# PIC16LF1567 register map
Vendor: Microchip
Architecture 16Exxx. Special function registers and configuration words.
Registers are 8-bit, read-write, no defined reset value unless marked. A register's access mark holds for its fields unless they carry their own. Addresses are absolute, and some are shared; only a register's first bit layout is shown; lines under a group give offsets from that group; [hi:lo] are bit positions; {n}, {i} and the like mark numbered series; 'fields as' and 'values as' point back to an identical list; <NAME> marks a mode.

## Further device data
pins=1: RE3/ICDMCLR/MCLR/VPP; 2: RA0/ADTX20/PWM10/SS1/AN20; 3: RA1/ADTX10/PWM11/SS2/AN10; 4: RA2/ADTX0/PWM12/AN0/VREFMINUS; 5: RA3/ADTX1/PWM13/AN1/VREFPLUS; 6: RA4/ADTX2/T0CKI/AN2; 7: RA5/ADTX21/SS1/AN21; 8: RE0/ADTX30/AN30; 9: RE1/ADTX41/AN41; 10: RE2/ADTX31/AN31; 11: VDD; 12: VSS/AVSS; 13: RA7/ADTX11/AN11/CLKIN; 14: RA6/ADTX22/AN22/CLKOUT; 15: RC0/ADTX12/SDO2/T1CKI/AN12; 16: RC1/ADTX23/PWM2/SCK2/SCL2/AN23; 17: RC2/ADTX13/PWM1/SDI2/SDA2/AN13; 18: RC3/ADTX24/SCK1/SCL1/AN24; 19: RD0/ADTX42/AN42; 20: RD1/ADTX32/AN32; 21: RD2/ADTX43/AN43; 22: RD3/ADTX33/AN33; 23: RC4/ADTX14/SDI1/SDA1/AN14; 24: RC5/ADTX25/SDO1/AN25; 25: RC6/ADTX15/TX/CK/AN15; 26: RC7/ADTX26/RX/DT/AN26; 27: RD4/ADTX34/AN34; 28: RD5/ADTX44/AN44; 29: RD6/ADTX35/AN35; 30: RD7/ADTX45/AN45; 31: VSS; 32: VDD/AVDD; 33: RB0/IOCB0/INT/ADTX16/PWM20/AN16; 34: RB1/IOCB1/ADTX27/PWM21/AN27; 35: RB2/IOCB2/ADTX17/PWM22/AN17; 36: RB3/IOCB3/ADTX28/PWM23/AN28; 37: RB4/IOCB4/ADTX18/AD2GRDA/AD1GRDA/AN18; 38: RB5/IOCB5/ADTX29/T1G/AD2GRDA/AD1GRDA/AN29; 39: RB6/IOCB6/ADTX19/AD2GRDB/AD1GRDB/AN19/ICDCLK/ICSPCLK; 40: RB7/IOCB7/ADTX40/AD2GRDB/AD1GRDB/AN40/ICDDAT/ICSPDAT

## mssp
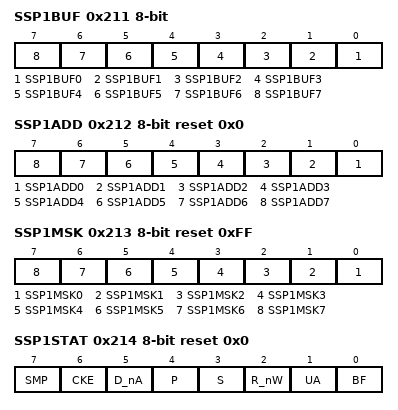
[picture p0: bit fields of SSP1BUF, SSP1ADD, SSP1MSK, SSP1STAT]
0x211 SSP1BUF — (power-on value xxxxxxxx)
  [n] SSP1BUF{n} (n=0..7)
0x212 SSP1ADD reset 0x0
  [n] SSP1ADD{n} (n=0..7)
0x213 SSP1MSK reset 0xFF
  [n] SSP1MSK{n} (n=0..7)
0x214 SSP1STAT reset 0x0
  [7] SMP, [6] CKE, [5] D_nA ro, [4] P ro, [3] S ro, [2] R_nW ro, [1] UA ro, [0] BF ro
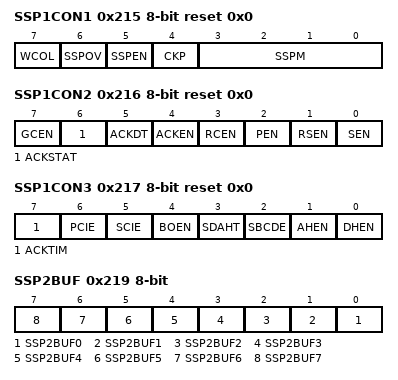
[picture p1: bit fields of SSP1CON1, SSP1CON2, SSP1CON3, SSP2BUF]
0x215 SSP1CON1 reset 0x0
  [7] WCOL, [6] SSPOV, [5] SSPEN, [4] CKP, [3:0] SSPM
0x216 SSP1CON2 reset 0x0
  [7] GCEN, [6] ACKSTAT ro, [5] ACKDT, [4] ACKEN, [3] RCEN, [2] PEN, [1] RSEN, [0] SEN
0x217 SSP1CON3 reset 0x0
  [7] ACKTIM ro, [6] PCIE, [5] SCIE, [4] BOEN, [3] SDAHT, [2] SBCDE, [1] AHEN, [0] DHEN
0x219 SSP2BUF — (power-on value xxxxxxxx)
  [n] SSP2BUF{n} (n=0..7)
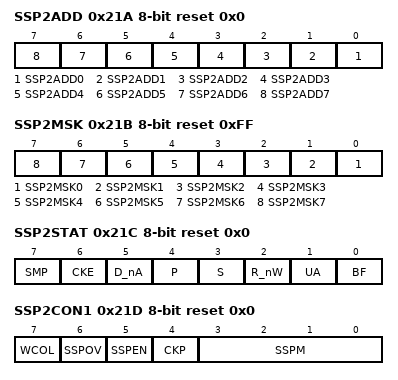
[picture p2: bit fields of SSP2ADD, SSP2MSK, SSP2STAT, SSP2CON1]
0x21A SSP2ADD reset 0x0
  [n] SSP2ADD{n} (n=0..7)
0x21B SSP2MSK reset 0xFF
  [n] SSP2MSK{n} (n=0..7)
0x21C SSP2STAT reset 0x0
  fields as SSP1STAT
0x21D SSP2CON1 reset 0x0
  [7] WCOL, [6] SSPOV, [5] SSPEN, [4] CKP, [3:0] SSPM
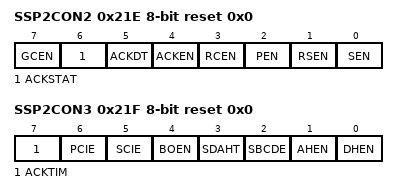
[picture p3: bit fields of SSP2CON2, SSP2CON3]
0x21E SSP2CON2 reset 0x0
  fields as SSP1CON2
0x21F SSP2CON3 reset 0x0
  fields as SSP1CON3

## CONFIG — Configuration words, addresses in ProgramSpace
0x8007 CONFIG1 14-bit reset 0x3FFF
  [11] CLKOUTEN — Clock Out Enable
    1=OFF (CLKOUT function is disabled. I/O or oscillator function on the CLKOUT pin); 0=ON (CLKOUT function is enabled on the CLKOUT pin)
  [10:9] BOREN — Brown-out Reset Enable
    3=ON (Brown-out Reset enabled); 2=NSLEEP (Brown-out Reset enabled while running and disabled in Sleep. SBOREN bit is ignored.); 1=SBODEN (Brown-out Reset controlled by the SBOREN bit in the BORCON register); 0=OFF (Brown-out Reset disabled. SBOREN bit is ignored.)
  [7] CP — Flash Program Memory Code Protection
    1=OFF (Program memory code protection is disabled); 0=ON (Program memory code protection is enabled)
  [6] MCLRE — MCLR Pin Function Select
    1=ON (MCLR/VPP pin function is MCLR); 0=OFF (MCLR/VPP pin function is digital input)
  [5] PWRTE — Power-up Timer Enable
    1=OFF (PWRT disabled); 0=ON (PWRT enabled)
  [4:3] WDTE — Watchdog Timer Enable
    3=ON (WDT enabled. SWDTEN bit is ignored.); 2=NSLEEP (WDT enabled while running and disabled in Sleep. SWDTEN bit is ignored.); 1=SWDTEN (WDT controlled by the SWDTEN bit in the WDTCON register); 0=OFF (WDT disabled. SWDTEN bit is ignored.)
  [1:0] FOSC — Oscillator Selection Bits
    3=ECH (ECH, External Clock, High Power Mode (4-20 MHz): device clock supplied to CLKIN pins); 2=ECM (ECM, External Clock, Medium Power Mode (0.5-4 MHz): device clock supplied to CLKIN pins); 1=ECL (ECL, External Clock, Low Power Mode (0-0.5 MHz): device clock supplied to CLKIN pins); 0=INTOSC (INTOSC oscillator: I/O function on CLKIN pin)
0x8008 CONFIG2 14-bit reset 0x3FFF
  [13] LVP — Low-Voltage Programming Enable
    1=ON (Low-voltage programming enabled); 0=OFF (High-voltage on MCLR/VPP must be used for programming)
  [12] DEBUG — In-Circuit Debugger Mode
    1=OFF (In-Circuit Debugger disabled, ICSPCLK and ICSPDAT are general purpose I/O pins); 0=ON (In-Circuit Debugger enabled, ICSPCLK and ICSPDAT are dedicated to the debugger)
  [11] LPBOR — Low-Power Brown Out Reset
    1=OFF (Low-Power BOR is disabled); 0=ON (Low-Power BOR is enabled)
  [10] BORV — Brown-out Reset Voltage Selection
    1=LO (Brown-out Reset Voltage (Vbor), 1.9V trip point selected.); 0=HI (Brown-out Reset Voltage (Vbor), 2.7V trip point selected.)
  [9] STVREN — Stack Overflow/Underflow Reset Enable
    1=ON (Stack Overflow or Underflow will cause a Reset); 0=OFF (Stack Overflow or Underflow will not cause a Reset)
  [1:0] WRT — Flash Memory Self-Write Protection
    3=OFF (Write protection off); 2=BOOT (000h to 1FFh write protected, 200h to FFFh may be modified by PMCON control); 1=HALF (000h to 7FFh write protected, 800h to FFFh may be modified by PMCON control); 0=ALL (000h to FFFh write protected, no addresses may be modified by PMCON control)
